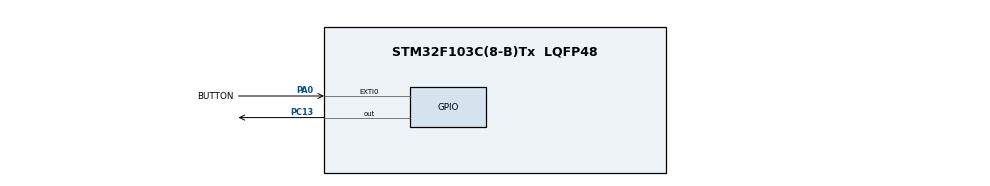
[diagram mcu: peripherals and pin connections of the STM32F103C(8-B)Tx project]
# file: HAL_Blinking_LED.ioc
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Mcu.Family=STM32F1
Mcu.Name=STM32F103C(8-B)Tx
Mcu.Package=LQFP48
NVIC.EXTI0_IRQn=true\:1\:0\:true\:false\:true\:true\:true\:true
NVIC.PriorityGroup=NVIC_PRIORITYGROUP_4
NVIC.TIM3_IRQn=true\:0\:0\:false\:false\:true\:true\:true\:true
PA0-WKUP.GPIO_Label=BUTTON
PA0-WKUP.GPIO_PuPd=GPIO_PULLUP
PA0-WKUP.Signal=GPXTI0
PC13-TAMPER-RTC.Signal=GPIO_Output
PD0-OSC_IN.Mode=HSE-External-Oscillator
PD0-OSC_IN.Signal=RCC_OSC_IN
PD1-OSC_OUT.Mode=HSE-External-Oscillator
PD1-OSC_OUT.Signal=RCC_OSC_OUT
ProjectManager.HeapSize=0x200
ProjectManager.StackSize=0x400
ProjectManager.TargetToolchain=STM32CubeIDE
RCC.AHBFreq_Value=8000000
RCC.APB1Freq_Value=8000000
RCC.APB1TimFreq_Value=8000000
RCC.APB2Freq_Value=8000000
RCC.APB2TimFreq_Value=8000000
RCC.HCLKFreq_Value=8000000
RCC.PLLSourceVirtual=RCC_PLLSOURCE_HSE
RCC.SYSCLKSource=RCC_SYSCLKSOURCE_HSE
RCC.USBFreq_Value=16000000
TIM3.AutoReloadPreload=TIM_AUTORELOAD_PRELOAD_ENABLE
TIM3.Period=500
TIM3.Prescaler=8000
VP_SYS_VS_ND.Mode=No_Debug
VP_TIM3_VS_ClockSourceINT.Mode=Internal
board=custom

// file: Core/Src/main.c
/* USER CODE BEGIN Header */
/**
  ******************************************************************************
  * @file           : main.c
  * @brief          : Main program body
  ******************************************************************************
  * @attention
  *
  * Copyright (c) 2024 STMicroelectronics.
  * All rights reserved.
  *
  * This software is licensed under terms that can be found in the LICENSE file
  * in the root directory of this software component.
  * If no LICENSE file comes with this software, it is provided AS-IS.
  *
  ******************************************************************************
  */
/* USER CODE END Header */
#include "main.h"

TIM_HandleTypeDef htim3;

void SystemClock_Config(void);
static void MX_GPIO_Init(void);
static void MX_TIM3_Init(void);

int main(void)
{

  /* MCU Configuration--------------------------------------------------------*/

  /* Reset of all peripherals, Initializes the Flash interface and the Systick. */
  HAL_Init();

  /* Configure the system clock */
  SystemClock_Config();

  /* Initialize all configured peripherals */
  MX_GPIO_Init();
  MX_TIM3_Init();
  /* USER CODE BEGIN 2 */
  HAL_TIM_Base_Start_IT(&htim3);
  //__HAL_TIM_ENABLE_IT(&htim3, TIM_IT_CC1);
  /* USER CODE END 2 */

  /* Infinite loop */
  while (1)
  {

  }
}

void SystemClock_Config(void)
{
  RCC_OscInitTypeDef RCC_OscInitStruct = {0};
  RCC_ClkInitTypeDef RCC_ClkInitStruct = {0};

  /** Initializes the RCC Oscillators according to the specified parameters
  * in the RCC_OscInitTypeDef structure.
  */
  RCC_OscInitStruct.OscillatorType = RCC_OSCILLATORTYPE_HSE;
  RCC_OscInitStruct.HSEState = RCC_HSE_ON;
  RCC_OscInitStruct.PLL.PLLState = RCC_PLL_NONE;
  if (HAL_RCC_OscConfig(&RCC_OscInitStruct) != HAL_OK)
  {
    Error_Handler();
  }

  /** Initializes the CPU, AHB and APB buses clocks
  */
  RCC_ClkInitStruct.ClockType = RCC_CLOCKTYPE_HCLK|RCC_CLOCKTYPE_SYSCLK
                              |RCC_CLOCKTYPE_PCLK1|RCC_CLOCKTYPE_PCLK2;
  RCC_ClkInitStruct.SYSCLKSource = RCC_SYSCLKSOURCE_HSE;
  RCC_ClkInitStruct.AHBCLKDivider = RCC_SYSCLK_DIV1;
  RCC_ClkInitStruct.APB1CLKDivider = RCC_HCLK_DIV1;
  RCC_ClkInitStruct.APB2CLKDivider = RCC_HCLK_DIV1;

  if (HAL_RCC_ClockConfig(&RCC_ClkInitStruct, FLASH_LATENCY_0) != HAL_OK)
  {
    Error_Handler();
  }
}

static void MX_TIM3_Init(void)
{

  TIM_ClockConfigTypeDef sClockSourceConfig = {0};
  TIM_MasterConfigTypeDef sMasterConfig = {0};

  htim3.Instance = TIM3;
  htim3.Init.Prescaler = 8000;
  htim3.Init.CounterMode = TIM_COUNTERMODE_UP;
  htim3.Init.Period = 500;
  htim3.Init.ClockDivision = TIM_CLOCKDIVISION_DIV1;
  htim3.Init.AutoReloadPreload = TIM_AUTORELOAD_PRELOAD_ENABLE;
  if (HAL_TIM_Base_Init(&htim3) != HAL_OK)
  {
    Error_Handler();
  }
  sClockSourceConfig.ClockSource = TIM_CLOCKSOURCE_INTERNAL;
  if (HAL_TIM_ConfigClockSource(&htim3, &sClockSourceConfig) != HAL_OK)
  {
    Error_Handler();
  }
  sMasterConfig.MasterOutputTrigger = TIM_TRGO_RESET;
  sMasterConfig.MasterSlaveMode = TIM_MASTERSLAVEMODE_DISABLE;
  if (HAL_TIMEx_MasterConfigSynchronization(&htim3, &sMasterConfig) != HAL_OK)
  {
    Error_Handler();
  }

}

static void MX_GPIO_Init(void)
{
  GPIO_InitTypeDef GPIO_InitStruct = {0};

  /* GPIO Ports Clock Enable */
  __HAL_RCC_GPIOC_CLK_ENABLE();
  __HAL_RCC_GPIOD_CLK_ENABLE();
  __HAL_RCC_GPIOA_CLK_ENABLE();

  /*Configure GPIO pin Output Level */
  HAL_GPIO_WritePin(GPIOC, GPIO_PIN_13, GPIO_PIN_RESET);

  /*Configure GPIO pin : PC13 */
  GPIO_InitStruct.Pin = GPIO_PIN_13;
  GPIO_InitStruct.Mode = GPIO_MODE_OUTPUT_PP;
  GPIO_InitStruct.Pull = GPIO_NOPULL;
  GPIO_InitStruct.Speed = GPIO_SPEED_FREQ_LOW;
  HAL_GPIO_Init(GPIOC, &GPIO_InitStruct);

  /*Configure GPIO pin : BUTTON_Pin */
  GPIO_InitStruct.Pin = BUTTON_Pin;
  GPIO_InitStruct.Mode = GPIO_MODE_IT_RISING;
  GPIO_InitStruct.Pull = GPIO_PULLUP;
  HAL_GPIO_Init(BUTTON_GPIO_Port, &GPIO_InitStruct);

  /* EXTI interrupt init*/
  HAL_NVIC_SetPriority(EXTI0_IRQn, 1, 0);
  HAL_NVIC_EnableIRQ(EXTI0_IRQn);

}

/* USER CODE BEGIN 4 */
void HAL_TIM_PeriodElapsedCallback(TIM_HandleTypeDef *htim)
{
	HAL_GPIO_TogglePin(GPIOC, GPIO_PIN_13);
}

void HAL_GPIO_EXTI_Callback(uint16_t GPIO_Pin)
{
	if(GPIO_Pin == GPIO_PIN_0)
	{
		HAL_TIM_Base_Stop_IT(&htim3);
	}
}

/* USER CODE END 4 */

void Error_Handler(void)
{
  __disable_irq();
  while (1)
  {
  }
}
